# LPC8N04 register map
File version: 0.1
LPC8N04 description
CPU: CM0PLUS r0p0, little endian, no MPU, no FPU, 2 interrupt priority bits
Registers are 32-bit, read-write, no defined reset value unless marked. A register's access mark holds for its fields unless they carry their own. Offsets are from the block's base; lines under a group give offsets from that group; [hi:lo] are bit positions; {n}, {i} and the like mark numbered series; 'fields as' and 'values as' point back to an identical list; <NAME> marks a mode.

## Memory map
0x40000000 I2C0 size 0xFFF — I2C Bus Controller 0
0x40004000 WDT size 0xFFF — Watchdog Timer
0x4000C000 TIMER16_0 size 0xFFF — 16-bit counter/timer 0
0x40014000 TIMER32_0 size 0xFFF — 32-bit counter/timer 0
0x40034000 EEPROM size 0xFFF — EEPROM controller
0x40038000 PMU size 0xFFF — Power Management Unit
0x4003C000 FLASH size 0xFFF — Flash controller
0x40040000 SPI0 size 0xFFF — Serial Peripheral Interface (SPI)
0x40044000 IOCON size 0xFFF — IO configuration
0x40048000 SYSCON size 0xFFF — System Configuration
0x40054000 RTC size 0xFFF — Real time clock timer
0x40058000 RFIDNFC size 0xFFF — RFID and NFC
0x40060000 TSEN size 0xFFF — Temperature Sensor
0x50008000 GPIO size 0xFFF — General Purpose IO

## WDT — Watchdog Timer
Base 0x40004000
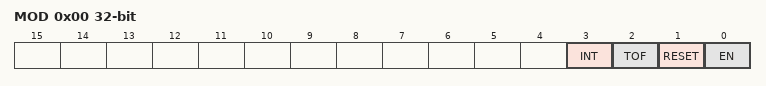
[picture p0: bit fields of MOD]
0x00 MOD — Watchdog mode register. This register contains the basic mode and status of the Watchdog Timer.
  [3] INT ro — Watchdog interrupt flag (Read Only, not clearable by software).
  [2] TOF — Watchdog time-out flag. Set when the watchdog timer times out, cleared by software. (Read/write))
  [1] RESET wo — Watchdog reset enable bit (Set Only). When 1, a watchdog time-out will cause a chip reset.
  [0] EN wo — Watchdog enable bit (Set Only). When 1, the watchdog timer is running.
0x04 TC reset 0xFF (reset mask 0x0) — Watchdog timer constant register. This register determines the time-out value.
  [23:0] Count — Watchdog time-out interval
0x08 FEED wo reset 0xFFFFFFFF (reset mask 0x0) — Watchdog feed sequence register. Writing 0xAA followed by 0x55 to this register reloads the Watchdog timer with the value contained in WDTC.
  [7:0] Feed — Feed value should be 0xAA followed by 0x55
0x0C TV ro reset 0xFF (reset mask 0x0) — Watchdog timer value register. This register reads out the current value of the Watchdog timer.
  [23:0] Count — Counter timer value

## PMU — Power Management Unit
Base 0x40038000
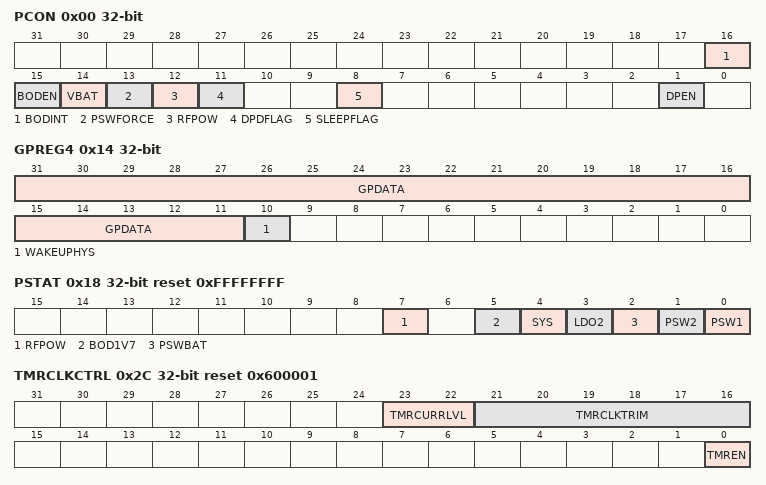
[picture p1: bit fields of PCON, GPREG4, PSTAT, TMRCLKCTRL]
0x00 PCON — Power control register
  [16] BODINT — BOD interrupt masking
    0=DISABLED (Disable interrupt when brown-out condition is detected, also clear the interrupt.); 1=ENABLED (Enable interrupt when brown-out condition is detected)
  [15] BODEN — Brown-out detector enable
    0=DISABLED (BOD disabled); 1=ENABLED (BOD enabled)
  [14] VBAT — This bit enables the connection of the VBAT pin to VDD, effectively connecting the system to the battery.
    0=NOT_CONNECTED (VBAT not connected to VDD); 1=CONNECTED (VBAT connected to VDD)
  [13] PSWFORCE — Force power switch state
    0=AUTO (Power switches are in automatic mode (as described in 4.4.1)); 1=FORCED (Power switches are forced to conduction (connect VDD_EXT and VDD_RFID). Only set this when on RF power and no external battery is present. Caution: any other usage of this feature can damage the IC.)
  [12] RFPOW — RFID/field power detect interrupt masking
    0=DISABLED (Disable interrupt when RF field power is detected, also clears the interrupt); 1=ENABLED (Enable interrupt when RF field power is detected)
  [11] DPDFLAG — Deep power-down flag
    0=CLEARED (read: No power-down mode entered / write: no effect); 1=SET (read:deep power-down mode entered / write: clear the deep power-down flag)
  [8] SLEEPFLAG — Sleep mode flag
    0=CLEARED (read: No power-down mode entered / write: no effect); 1=SET (read: sleep/deep-sleep mode entered / write: write 1 to clear SLEEPFLAG)
  [1] DPEN — Deep power-down mode enable
    0=DISABLED (ARM WFI will enter Sleep or Deep-sleep mode (clock to ARM Cortex M0+ core turned off)); 1=ENABLED (ARM WFI will enter Deep-power down mode (ARM Cortex M0+ core powered down))
{0x4+4i} GPREG{i} (i=0..3) — General purpose register {i}
  [31:0] GPDATA — Data retained during deep power-down mode
0x14 GPREG4 — General purpose register 4
  [31:11] GPDATA — Data retained during Deep power-down mode
  [10] WAKEUPHYS — WAKEUP pin hysteresis enable
    0=DISABLED; 1=ENABLED
0x18 PSTAT ro reset 0xFFFFFFFF (reset mask 0x0) — Power management unit status register
  [7] RFPOW — RF field detected
    0=NOT_DETECTED (No field); 1=DETECTED (RF field)
  [5] BOD1V7 — BOD detected (VDD less than 1.7 V)
    0=NOT_DETECTED (VDD larger than 1.7 V); 1=DETECTED (VDD less than= 1.7 V)
  [4] SYS — System state
    0=POWERING_UP; 1=ON (System on)
  [3] LDO2 — Status of LDO2
    0=DISABLED (LDO disabled); 1=ENABLED (LDO enabled)
  [2] PSWBAT — Status of VBAT power switch
    0=OPEN (Switch disabled (not conducting)); 1=CLOSED (Switch enabled (conducting))
  [1] PSW2 — Status of power switch 2
    values as PSWBAT
  [0] PSW1 — Status of power switch 1
    values as PSWBAT
0x20 ACCSTAT ro — Access status register
  [0] PMU_READY — (0) PMU access not possible, (1) PMU access possible
0x24 LDO1V6 reset 0x4 (reset mask 0x0) — Analog 1.6 V LDO trimming
  [3:0] TRIM1V6 — Trim value for analog LDO
0x2C TMRCLKCTRL reset 0x600001 (reset mask 0x0) — Timer clock control register
  [23:22] TMRCURRLVL — Timer FRO current level selector bits
  [21:16] TMRCLKTRIM — Timer FRO trim value (6-bit)
  [0] TMREN — RTC clock source.
    0=NO_CLOCK; 1=TFRO (32kHz FRO)
